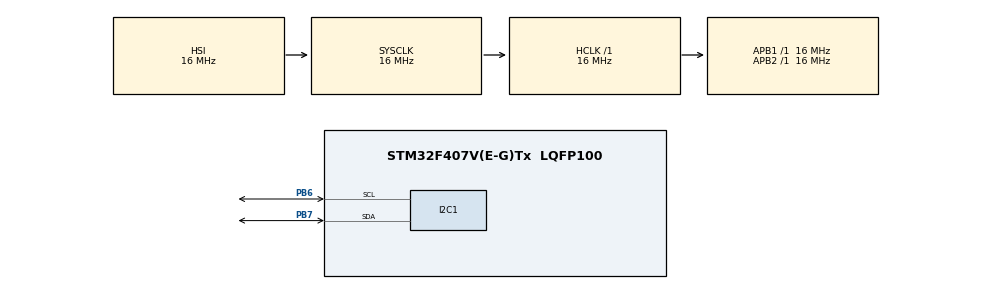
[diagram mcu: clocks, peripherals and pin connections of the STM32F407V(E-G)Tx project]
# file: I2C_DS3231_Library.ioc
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Mcu.Family=STM32F4
Mcu.Name=STM32F407V(E-G)Tx
Mcu.Package=LQFP100
NVIC.PriorityGroup=NVIC_PRIORITYGROUP_4
PB6.Mode=I2C
PB6.Signal=I2C1_SCL
PB7.Mode=I2C
PB7.Signal=I2C1_SDA
ProjectManager.HeapSize=0x200
ProjectManager.StackSize=0x400
ProjectManager.TargetToolchain=STM32CubeIDE
RCC.AHBFreq_Value=16000000
RCC.APB1Freq_Value=16000000
RCC.APB2Freq_Value=16000000
RCC.CortexFreq_Value=16000000
RCC.HSE_VALUE=25000000
RCC.HSI_VALUE=16000000
RCC.LSE_VALUE=32768
RCC.SYSCLKFreq_VALUE=16000000
RCC.VCOOutputFreq_Value=192000000
board=custom

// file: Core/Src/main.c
/* USER CODE BEGIN Header */
/**
 ******************************************************************************
 * @file           : main.c
 * @brief          : Main program body
 ******************************************************************************
 * @attention
 *
 * Copyright (c) 2026 STMicroelectronics.
 * All rights reserved.
 *
 * This software is licensed under terms that can be found in the LICENSE file
 * in the root directory of this software component.
 * If no LICENSE file comes with this software, it is provided AS-IS.
 *
 ******************************************************************************
 */
/* USER CODE END Header */
#include "main.h"

/* USER CODE BEGIN Includes */
#include "ds3231.h"
#include "ds3231_port_stm32.h"

/* USER CODE END Includes */

I2C_HandleTypeDef hi2c1;

/* USER CODE BEGIN PV */

/**
 * @brief DS3231 instance bound to hi2c1 (see DS3231_Port_STM32_Init() below).
 *        All DS3231_Set_Time() / DS3231_Get_Time() calls for this device
 *        must go through this handle.
 */
DS3231_Handle_t ds3231Handle;

/** @brief Most recently read date/time snapshot, refreshed every second
 *         in the main loop below. */
DS3231_Time_t ds3231Time;

/* USER CODE END PV */

void SystemClock_Config(void);
static void MX_GPIO_Init(void);
static void MX_I2C1_Init(void);

int main(void) {

	/* MCU Configuration--------------------------------------------------------*/

	/* Reset of all peripherals, Initializes the Flash interface and the Systick. */
	HAL_Init();

	/* Configure the system clock */
	SystemClock_Config();

	/* Initialize all configured peripherals */
	MX_GPIO_Init();
	MX_I2C1_Init();
	/* USER CODE BEGIN 2 */

	/*
	 uint8_t address = 0;

	 for (int i = 0; i< 255;i++){

	 if(HAL_I2C_IsDeviceReady(&hi2c1, i, 1, 100) == HAL_OK){

	 address = i;
	 }

	 }
	 */

	/* Bind ds3231Handle to the I2C1 peripheral (must run after
	 * MX_I2C1_Init()). */
	DS3231_Port_STM32_Init(&ds3231Handle, &hi2c1);

	/* One-time RTC provisioning: sec=0, min=22, hour=22, dayOfWeek=2,
	 * dayOfMonth=5, month=6, year=13. Intended for initial bring-up;
	 * remove or guard this call once the RTC has been set, otherwise
	 * the clock resets to this fixed time on every reboot. */
	DS3231_Set_Time(&ds3231Handle, 0, 22, 22, 2, 5, 6, 13);

	/* USER CODE END 2 */

	/* Infinite loop */
	while (1) {

		/* USER CODE BEGIN 3 */

		/* Poll the RTC once per second. On failure, ds3231Time keeps
		 * its last valid value (see DS3231_Get_Time() contract). */
		DS3231_Get_Time(&ds3231Handle, &ds3231Time);
		HAL_Delay(1000);
	}
	/* USER CODE END 3 */
}

void SystemClock_Config(void) {
	RCC_OscInitTypeDef RCC_OscInitStruct = { 0 };
	RCC_ClkInitTypeDef RCC_ClkInitStruct = { 0 };

	/** Configure the main internal regulator output voltage
	 */
	__HAL_RCC_PWR_CLK_ENABLE();
	__HAL_PWR_VOLTAGESCALING_CONFIG(PWR_REGULATOR_VOLTAGE_SCALE1);

	/** Initializes the RCC Oscillators according to the specified parameters
	 * in the RCC_OscInitTypeDef structure.
	 */
	RCC_OscInitStruct.OscillatorType = RCC_OSCILLATORTYPE_HSI;
	RCC_OscInitStruct.HSIState = RCC_HSI_ON;
	RCC_OscInitStruct.HSICalibrationValue = RCC_HSICALIBRATION_DEFAULT;
	RCC_OscInitStruct.PLL.PLLState = RCC_PLL_NONE;
	if (HAL_RCC_OscConfig(&RCC_OscInitStruct) != HAL_OK) {
		Error_Handler();
	}

	/** Initializes the CPU, AHB and APB buses clocks
	 */
	RCC_ClkInitStruct.ClockType = RCC_CLOCKTYPE_HCLK | RCC_CLOCKTYPE_SYSCLK
			| RCC_CLOCKTYPE_PCLK1 | RCC_CLOCKTYPE_PCLK2;
	RCC_ClkInitStruct.SYSCLKSource = RCC_SYSCLKSOURCE_HSI;
	RCC_ClkInitStruct.AHBCLKDivider = RCC_SYSCLK_DIV1;
	RCC_ClkInitStruct.APB1CLKDivider = RCC_HCLK_DIV1;
	RCC_ClkInitStruct.APB2CLKDivider = RCC_HCLK_DIV1;

	if (HAL_RCC_ClockConfig(&RCC_ClkInitStruct, FLASH_LATENCY_0) != HAL_OK) {
		Error_Handler();
	}
}

static void MX_I2C1_Init(void) {

	hi2c1.Instance = I2C1;
	hi2c1.Init.ClockSpeed = 100000;
	hi2c1.Init.DutyCycle = I2C_DUTYCYCLE_2;
	hi2c1.Init.OwnAddress1 = 0;
	hi2c1.Init.AddressingMode = I2C_ADDRESSINGMODE_7BIT;
	hi2c1.Init.DualAddressMode = I2C_DUALADDRESS_DISABLE;
	hi2c1.Init.OwnAddress2 = 0;
	hi2c1.Init.GeneralCallMode = I2C_GENERALCALL_DISABLE;
	hi2c1.Init.NoStretchMode = I2C_NOSTRETCH_DISABLE;
	if (HAL_I2C_Init(&hi2c1) != HAL_OK) {
		Error_Handler();
	}

}

static void MX_GPIO_Init(void) {

	/* GPIO Ports Clock Enable */
	__HAL_RCC_GPIOB_CLK_ENABLE();

}

void Error_Handler(void) {
	__disable_irq();
	while (1) {
	}
}
